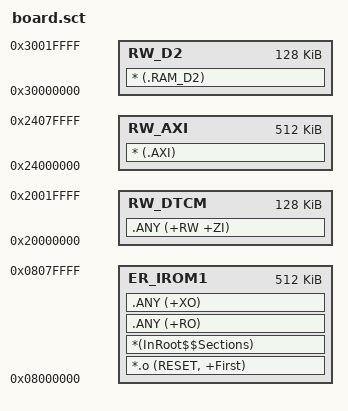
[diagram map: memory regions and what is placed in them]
LR_IROM1 0x08000000 0x00080000 {
 ER_IROM1 0x08000000 0x00080000 {
  *.o (RESET, +First)
  *(InRoot$$Sections)
  .ANY (+RO)
  .ANY (+XO)
 }
 RW_D2 0x30000000 0x00020000 { * (.RAM_D2) }
 RW_AXI 0x24000000 0x00080000 { * (.AXI) }
 RW_DTCM 0x20000000 0x00020000 { .ANY (+RW +ZI) }
}
